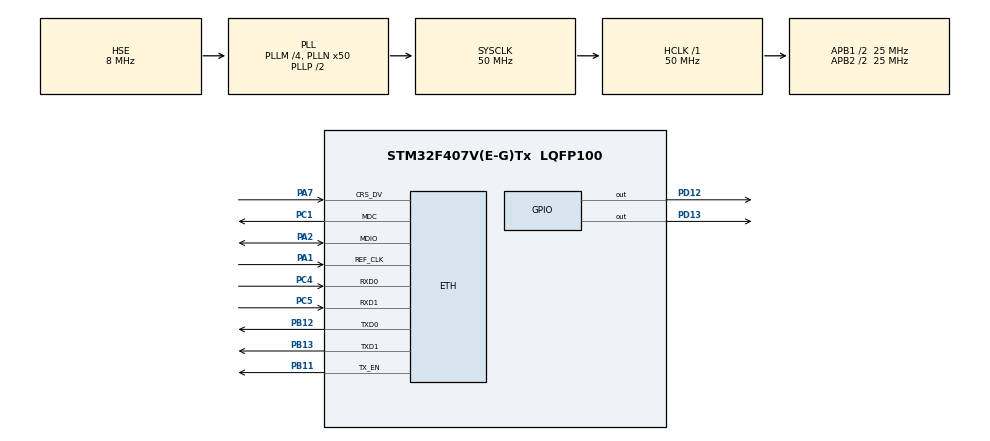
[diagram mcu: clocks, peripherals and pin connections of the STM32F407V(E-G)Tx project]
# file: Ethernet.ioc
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ETH.MediaInterface=HAL_ETH_RMII_MODE
ETH.PHY_Name_RMII=DP83848_PHY_ADDRESS
LWIP.BSP.number=1
LWIP.GATEWAY_ADDRESS=192.168.000.001
LWIP.IP_ADDRESS=192.168.001.111
LWIP.LWIP_DHCP=0
LWIP.LWIP_IPV6=0
LWIP.NETMASK_ADDRESS=255.255.255.000
LWIP.Version=v2.1.2_Cube
LWIP0.BSP.STBoard=false
LWIP0.BSP.api=BSP_COMPONENT_DRIVER
LWIP0.BSP.component=DP83848
LWIP0.BSP.instance=DP83848
LWIP0.BSP.name=Driver_PHY
LWIP0.BSP.semaphore=S_DP83848
LWIP0.BSP.solution=DP83848
Mcu.Family=STM32F4
Mcu.Name=STM32F407V(E-G)Tx
Mcu.Package=LQFP100
NVIC.PriorityGroup=NVIC_PRIORITYGROUP_0
PA1.Mode=RMII
PA1.Signal=ETH_REF_CLK
PA2.Mode=RMII
PA2.Signal=ETH_MDIO
PA7.Mode=RMII
PA7.Signal=ETH_CRS_DV
PB11.Mode=RMII
PB11.Signal=ETH_TX_EN
PB12.Mode=RMII
PB12.Signal=ETH_TXD0
PB13.Mode=RMII
PB13.Signal=ETH_TXD1
PC1.Mode=RMII
PC1.Signal=ETH_MDC
PC4.Mode=RMII
PC4.Signal=ETH_RXD0
PC5.Mode=RMII
PC5.Signal=ETH_RXD1
PD12.Signal=GPIO_Output
PD13.Signal=GPIO_Output
PH0-OSC_IN.Mode=HSE-External-Oscillator
PH0-OSC_IN.Signal=RCC_OSC_IN
PH1-OSC_OUT.Mode=HSE-External-Oscillator
PH1-OSC_OUT.Signal=RCC_OSC_OUT
ProjectManager.HeapSize=0x200
ProjectManager.StackSize=0x400
ProjectManager.TargetToolchain=STM32CubeIDE
RCC.48MHZClocksFreq_Value=14285714.285714285
RCC.AHBFreq_Value=50000000
RCC.APB1CLKDivider=RCC_HCLK_DIV2
RCC.APB1Freq_Value=25000000
RCC.APB1TimFreq_Value=50000000
RCC.APB2CLKDivider=RCC_HCLK_DIV2
RCC.APB2Freq_Value=25000000
RCC.APB2TimFreq_Value=50000000
RCC.CortexFreq_Value=50000000
RCC.HCLKFreq_Value=50000000
RCC.HSE_VALUE=8000000
RCC.HSI_VALUE=16000000
RCC.LSE_VALUE=32768
RCC.PLLM=4
RCC.PLLN=50
RCC.PLLQ=7
RCC.PLLSourceVirtual=RCC_PLLSOURCE_HSE
RCC.SYSCLKFreq_VALUE=50000000
RCC.SYSCLKSource=RCC_SYSCLKSOURCE_PLLCLK
RCC.VCOOutputFreq_Value=100000000
VP_LWIP_VS_Enabled.Mode=Enabled
board=STM32F407G-DISC1

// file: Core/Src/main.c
/* USER CODE BEGIN Header */
/**
  ******************************************************************************
  * @file           : main.c
  * @brief          : Main program body
  ******************************************************************************
  * @attention
  *
  * Copyright (c) 2022 STMicroelectronics.
  * All rights reserved.
  *
  * This software is licensed under terms that can be found in the LICENSE file
  * in the root directory of this software component.
  * If no LICENSE file comes with this software, it is provided AS-IS.
  *
  ******************************************************************************
  */
/* USER CODE END Header */
#include "main.h"
#include "lwip.h"

void SystemClock_Config(void);
static void MX_GPIO_Init(void);

/* USER CODE BEGIN 0 */
extern struct netif gnetif;
/* USER CODE END 0 */

int main(void)
{

  /* MCU Configuration--------------------------------------------------------*/

  /* Reset of all peripherals, Initializes the Flash interface and the Systick. */
  HAL_Init();

  /* Configure the system clock */
  SystemClock_Config();

  /* Initialize all configured peripherals */
  MX_GPIO_Init();
  MX_LWIP_Init();

  /* Infinite loop */
  while (1)
  {

    /* USER CODE BEGIN 3 */
	  HAL_GPIO_TogglePin(GPIOD, GPIO_PIN_13);
	  ethernetif_input(&gnetif);
	  sys_check_timeouts();
	  HAL_GPIO_TogglePin(GPIOD, GPIO_PIN_12);
	  HAL_Delay(100);
  }
  /* USER CODE END 3 */
}

void SystemClock_Config(void)
{
  RCC_OscInitTypeDef RCC_OscInitStruct = {0};
  RCC_ClkInitTypeDef RCC_ClkInitStruct = {0};

  /** Configure the main internal regulator output voltage
  */
  __HAL_RCC_PWR_CLK_ENABLE();
  __HAL_PWR_VOLTAGESCALING_CONFIG(PWR_REGULATOR_VOLTAGE_SCALE1);

  /** Initializes the RCC Oscillators according to the specified parameters
  * in the RCC_OscInitTypeDef structure.
  */
  RCC_OscInitStruct.OscillatorType = RCC_OSCILLATORTYPE_HSE;
  RCC_OscInitStruct.HSEState = RCC_HSE_ON;
  RCC_OscInitStruct.PLL.PLLState = RCC_PLL_ON;
  RCC_OscInitStruct.PLL.PLLSource = RCC_PLLSOURCE_HSE;
  RCC_OscInitStruct.PLL.PLLM = 4;
  RCC_OscInitStruct.PLL.PLLN = 50;
  RCC_OscInitStruct.PLL.PLLP = RCC_PLLP_DIV2;
  RCC_OscInitStruct.PLL.PLLQ = 7;
  if (HAL_RCC_OscConfig(&RCC_OscInitStruct) != HAL_OK)
  {
    Error_Handler();
  }

  /** Initializes the CPU, AHB and APB buses clocks
  */
  RCC_ClkInitStruct.ClockType = RCC_CLOCKTYPE_HCLK|RCC_CLOCKTYPE_SYSCLK
                              |RCC_CLOCKTYPE_PCLK1|RCC_CLOCKTYPE_PCLK2;
  RCC_ClkInitStruct.SYSCLKSource = RCC_SYSCLKSOURCE_PLLCLK;
  RCC_ClkInitStruct.AHBCLKDivider = RCC_SYSCLK_DIV1;
  RCC_ClkInitStruct.APB1CLKDivider = RCC_HCLK_DIV2;
  RCC_ClkInitStruct.APB2CLKDivider = RCC_HCLK_DIV2;

  if (HAL_RCC_ClockConfig(&RCC_ClkInitStruct, FLASH_LATENCY_1) != HAL_OK)
  {
    Error_Handler();
  }
}

static void MX_GPIO_Init(void)
{
  GPIO_InitTypeDef GPIO_InitStruct = {0};

  /* GPIO Ports Clock Enable */
  __HAL_RCC_GPIOH_CLK_ENABLE();
  __HAL_RCC_GPIOC_CLK_ENABLE();
  __HAL_RCC_GPIOA_CLK_ENABLE();
  __HAL_RCC_GPIOB_CLK_ENABLE();
  __HAL_RCC_GPIOD_CLK_ENABLE();

  /*Configure GPIO pin Output Level */
  HAL_GPIO_WritePin(GPIOD, GPIO_PIN_12|GPIO_PIN_13, GPIO_PIN_RESET);

  /*Configure GPIO pins : PD12 PD13 */
  GPIO_InitStruct.Pin = GPIO_PIN_12|GPIO_PIN_13;
  GPIO_InitStruct.Mode = GPIO_MODE_OUTPUT_PP;
  GPIO_InitStruct.Pull = GPIO_NOPULL;
  GPIO_InitStruct.Speed = GPIO_SPEED_FREQ_LOW;
  HAL_GPIO_Init(GPIOD, &GPIO_InitStruct);

}

void Error_Handler(void)
{
  __disable_irq();
  while (1)
  {
  }
}
